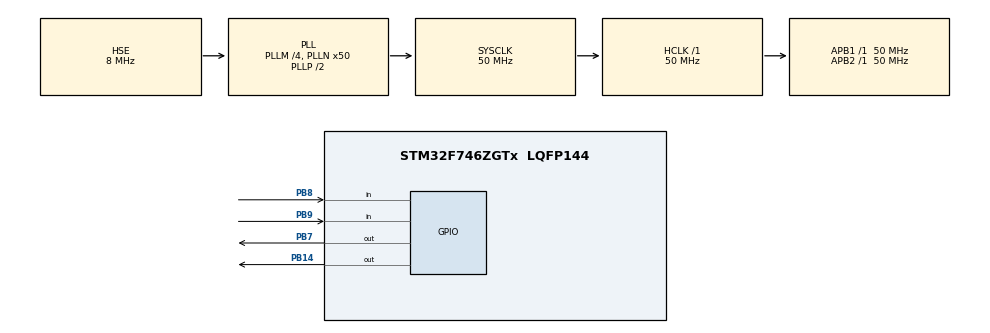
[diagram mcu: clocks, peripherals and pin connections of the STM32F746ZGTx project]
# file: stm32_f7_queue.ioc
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CORTEX_M7.default_mode_Activation=1
FREERTOS.BinarySemaphores01=myBinarySem01,Dynamic,NULL,Available
FREERTOS.Mutexes01=myMutex01,Dynamic,NULL,Available
FREERTOS.Queues01=myQueue01,16,uint16_t,0,Dynamic,NULL,NULL
FREERTOS.Tasks01=defaultTask,24,128,StartDefaultTask,Default,NULL,Dynamic,NULL,NULL;myTask02,24,128,StartTask02,Default,NULL,Dynamic,NULL,NULL
FREERTOS.configUSE_NEWLIB_REENTRANT=1
Mcu.Family=STM32F7
Mcu.Name=STM32F746ZGTx
Mcu.Package=LQFP144
NVIC.PriorityGroup=NVIC_PRIORITYGROUP_4
PB14.Signal=GPIO_Output
PB7.Signal=GPIO_Output
PB8.GPIO_PuPd=GPIO_PULLUP
PB8.Signal=GPIO_Input
PB9.GPIO_PuPd=GPIO_PULLUP
PB9.Signal=GPIO_Input
PH0/OSC_IN.Mode=HSE-External-Oscillator
PH0/OSC_IN.Signal=RCC_OSC_IN
PH1/OSC_OUT.Mode=HSE-External-Oscillator
PH1/OSC_OUT.Signal=RCC_OSC_OUT
ProjectManager.HeapSize=0x200
ProjectManager.StackSize=0x400
ProjectManager.TargetToolchain=STM32CubeIDE
RCC.AHBFreq_Value=50000000
RCC.APB1Freq_Value=50000000
RCC.APB1TimFreq_Value=50000000
RCC.APB2Freq_Value=50000000
RCC.APB2TimFreq_Value=50000000
RCC.CortexFreq_Value=50000000
RCC.HCLKFreq_Value=50000000
RCC.HSE_VALUE=8000000
RCC.HSI_VALUE=16000000
RCC.LSE_VALUE=32768
RCC.PLLM=4
RCC.PLLN=50
RCC.PLLSourceVirtual=RCC_PLLSOURCE_HSE
RCC.SYSCLKFreq_VALUE=50000000
RCC.SYSCLKSource=RCC_SYSCLKSOURCE_PLLCLK
RCC.USBFreq_Value=50000000
RCC.VCOOutputFreq_Value=100000000
VP_FREERTOS_VS_CMSIS_V2.Mode=CMSIS_V2
board=custom

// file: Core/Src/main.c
/* USER CODE BEGIN Header */
/**
  ******************************************************************************
  * @file           : main.c
  * @brief          : Main program body
  ******************************************************************************
  * @attention
  *
  * Copyright (c) 2025 STMicroelectronics.
  * All rights reserved.
  *
  * This software is licensed under terms that can be found in the LICENSE file
  * in the root directory of this software component.
  * If no LICENSE file comes with this software, it is provided AS-IS.
  *
  ******************************************************************************
  */
/* USER CODE END Header */
#include "main.h"
#include "cmsis_os.h"

/* Definitions for defaultTask */
osThreadId_t defaultTaskHandle;
const osThreadAttr_t defaultTask_attributes = {
  .name = "defaultTask",
  .stack_size = 128 * 4,
  .priority = (osPriority_t) osPriorityNormal,
};
/* Definitions for myTask02 */
osThreadId_t myTask02Handle;
const osThreadAttr_t myTask02_attributes = {
  .name = "myTask02",
  .stack_size = 128 * 4,
  .priority = (osPriority_t) osPriorityNormal,
};
/* Definitions for myQueue01 */
osMessageQueueId_t myQueue01Handle;
const osMessageQueueAttr_t myQueue01_attributes = {
  .name = "myQueue01"
};
/* Definitions for myMutex01 */
osMutexId_t myMutex01Handle;
const osMutexAttr_t myMutex01_attributes = {
  .name = "myMutex01"
};
/* Definitions for myBinarySem01 */
osSemaphoreId_t myBinarySem01Handle;
const osSemaphoreAttr_t myBinarySem01_attributes = {
  .name = "myBinarySem01"
};

void SystemClock_Config(void);
static void MPU_Config(void);
static void MX_GPIO_Init(void);
void StartDefaultTask(void *argument);
void StartTask02(void *argument);

/* USER CODE BEGIN 0 */
uint32_t receivedValue;
/* USER CODE END 0 */

int main(void)
{

  /* MPU Configuration--------------------------------------------------------*/
  MPU_Config();

  /* MCU Configuration--------------------------------------------------------*/

  /* Reset of all peripherals, Initializes the Flash interface and the Systick. */
  HAL_Init();

  /* Configure the system clock */
  SystemClock_Config();

  /* Initialize all configured peripherals */
  MX_GPIO_Init();

  /* Init scheduler */
  osKernelInitialize();
  /* Create the mutex(es) */
  /* creation of myMutex01 */
  myMutex01Handle = osMutexNew(&myMutex01_attributes);

  /* Create the semaphores(s) */
  /* creation of myBinarySem01 */
  myBinarySem01Handle = osSemaphoreNew(1, 1, &myBinarySem01_attributes);

  /* Create the queue(s) */
  /* creation of myQueue01 */
  myQueue01Handle = osMessageQueueNew (16, sizeof(uint16_t), &myQueue01_attributes);

  /* Create the thread(s) */
  /* creation of defaultTask */
  defaultTaskHandle = osThreadNew(StartDefaultTask, NULL, &defaultTask_attributes);

  /* creation of myTask02 */
  myTask02Handle = osThreadNew(StartTask02, NULL, &myTask02_attributes);

  /* Start scheduler */
  osKernelStart();

  /* We should never get here as control is now taken by the scheduler */

  /* Infinite loop */
  while (1)
  {

  }
}

void SystemClock_Config(void)
{
  RCC_OscInitTypeDef RCC_OscInitStruct = {0};
  RCC_ClkInitTypeDef RCC_ClkInitStruct = {0};

  /** Configure the main internal regulator output voltage
  */
  __HAL_RCC_PWR_CLK_ENABLE();
  __HAL_PWR_VOLTAGESCALING_CONFIG(PWR_REGULATOR_VOLTAGE_SCALE3);

  /** Initializes the RCC Oscillators according to the specified parameters
  * in the RCC_OscInitTypeDef structure.
  */
  RCC_OscInitStruct.OscillatorType = RCC_OSCILLATORTYPE_HSE;
  RCC_OscInitStruct.HSEState = RCC_HSE_ON;
  RCC_OscInitStruct.PLL.PLLState = RCC_PLL_ON;
  RCC_OscInitStruct.PLL.PLLSource = RCC_PLLSOURCE_HSE;
  RCC_OscInitStruct.PLL.PLLM = 4;
  RCC_OscInitStruct.PLL.PLLN = 50;
  RCC_OscInitStruct.PLL.PLLP = RCC_PLLP_DIV2;
  RCC_OscInitStruct.PLL.PLLQ = 2;
  if (HAL_RCC_OscConfig(&RCC_OscInitStruct) != HAL_OK)
  {
    Error_Handler();
  }

  /** Activate the Over-Drive mode
  */
  if (HAL_PWREx_EnableOverDrive() != HAL_OK)
  {
    Error_Handler();
  }

  /** Initializes the CPU, AHB and APB buses clocks
  */
  RCC_ClkInitStruct.ClockType = RCC_CLOCKTYPE_HCLK|RCC_CLOCKTYPE_SYSCLK
                              |RCC_CLOCKTYPE_PCLK1|RCC_CLOCKTYPE_PCLK2;
  RCC_ClkInitStruct.SYSCLKSource = RCC_SYSCLKSOURCE_PLLCLK;
  RCC_ClkInitStruct.AHBCLKDivider = RCC_SYSCLK_DIV1;
  RCC_ClkInitStruct.APB1CLKDivider = RCC_HCLK_DIV1;
  RCC_ClkInitStruct.APB2CLKDivider = RCC_HCLK_DIV1;

  if (HAL_RCC_ClockConfig(&RCC_ClkInitStruct, FLASH_LATENCY_1) != HAL_OK)
  {
    Error_Handler();
  }
}

static void MX_GPIO_Init(void)
{
  GPIO_InitTypeDef GPIO_InitStruct = {0};

  /* GPIO Ports Clock Enable */
  __HAL_RCC_GPIOH_CLK_ENABLE();
  __HAL_RCC_GPIOB_CLK_ENABLE();

  /*Configure GPIO pin Output Level */
  HAL_GPIO_WritePin(GPIOB, GPIO_PIN_14|GPIO_PIN_7, GPIO_PIN_RESET);

  /*Configure GPIO pins : PB14 PB7 */
  GPIO_InitStruct.Pin = GPIO_PIN_14|GPIO_PIN_7;
  GPIO_InitStruct.Mode = GPIO_MODE_OUTPUT_PP;
  GPIO_InitStruct.Pull = GPIO_NOPULL;
  GPIO_InitStruct.Speed = GPIO_SPEED_FREQ_LOW;
  HAL_GPIO_Init(GPIOB, &GPIO_InitStruct);

  /*Configure GPIO pins : PB8 PB9 */
  GPIO_InitStruct.Pin = GPIO_PIN_8|GPIO_PIN_9;
  GPIO_InitStruct.Mode = GPIO_MODE_INPUT;
  GPIO_InitStruct.Pull = GPIO_PULLUP;
  HAL_GPIO_Init(GPIOB, &GPIO_InitStruct);

}

void StartDefaultTask(void *argument)
{
  /* USER CODE BEGIN 5 */
	uint32_t value = 0;
	osSemaphoreAcquire(myBinarySem01Handle, osWaitForever);
  /* Infinite loop */
  for(;;)
  {
	  if(HAL_GPIO_ReadPin(GPIOB,GPIO_PIN_8) == RESET){
//		  if(osMutexAcquire(myMutex01Handle, osWaitForever)==osOK){
		  HAL_GPIO_TogglePin(GPIOB, GPIO_PIN_7);
//		  osMutexRelease(myMutex01Handle);
//		  value++;
//		  osMessageQueuePut(myQueue01Handle, &value, 0, osWaitForever);
		  osSemaphoreRelease(myBinarySem01Handle);
		  osDelay(1000);
//	  }
	  }
  }
  /* USER CODE END 5 */
}

void StartTask02(void *argument)
{
  /* USER CODE BEGIN StartTask02 */
	osSemaphoreAcquire(myBinarySem01Handle, osWaitForever);
  /* Infinite loop */
  for(;;)
  {
	  if(HAL_GPIO_ReadPin(GPIOB,GPIO_PIN_9) == RESET){
//		  if(osMutexAcquire(myMutex01Handle, osWaitForever)==osOK){
		  HAL_GPIO_TogglePin(GPIOB, GPIO_PIN_14);
//		  osMutexRelease(myMutex01Handle);
//		  osMessageQueueGet(myQueue01Handle, &receivedValue, NULL, osWaitForever);
		  osSemaphoreRelease(myBinarySem01Handle);
		  osDelay(1000);
//	  }
	  }
    osDelay(1);
  }
  /* USER CODE END StartTask02 */
}

 /* MPU Configuration */

void MPU_Config(void)
{
  MPU_Region_InitTypeDef MPU_InitStruct = {0};

  /* Disables the MPU */
  HAL_MPU_Disable();

  /** Initializes and configures the Region and the memory to be protected
  */
  MPU_InitStruct.Enable = MPU_REGION_ENABLE;
  MPU_InitStruct.Number = MPU_REGION_NUMBER0;
  MPU_InitStruct.BaseAddress = 0x0;
  MPU_InitStruct.Size = MPU_REGION_SIZE_4GB;
  MPU_InitStruct.SubRegionDisable = 0x87;
  MPU_InitStruct.TypeExtField = MPU_TEX_LEVEL0;
  MPU_InitStruct.AccessPermission = MPU_REGION_NO_ACCESS;
  MPU_InitStruct.DisableExec = MPU_INSTRUCTION_ACCESS_DISABLE;
  MPU_InitStruct.IsShareable = MPU_ACCESS_SHAREABLE;
  MPU_InitStruct.IsCacheable = MPU_ACCESS_NOT_CACHEABLE;
  MPU_InitStruct.IsBufferable = MPU_ACCESS_NOT_BUFFERABLE;

  HAL_MPU_ConfigRegion(&MPU_InitStruct);
  /* Enables the MPU */
  HAL_MPU_Enable(MPU_PRIVILEGED_DEFAULT);

}

void Error_Handler(void)
{
  __disable_irq();
  while (1)
  {
  }
}
